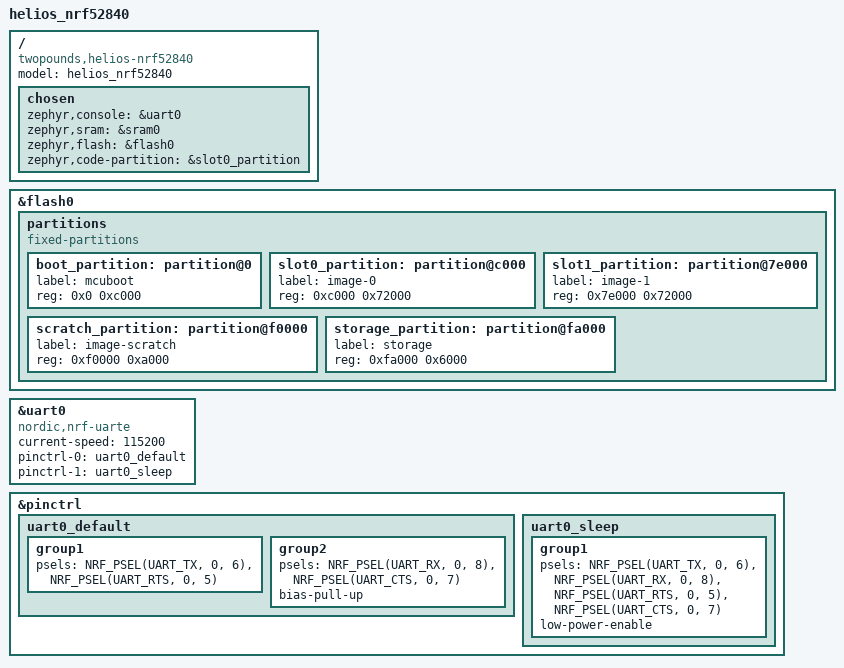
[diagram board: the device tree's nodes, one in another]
// Copyright (c) 2023 Nordic Semiconductor ASA
// SPDX-License-Identifier: Apache-2.0

/dts-v1/;
#include <nordic/nrf52840_qiaa.dtsi>

/ {
	model = "helios_nrf52840";
	compatible = "twopounds,helios-nrf52840";

	chosen {
		// zephyr,console = &cdc_acm_uart1; // original from manuel
		zephyr,console = &uart0; // inserted by jowi 5.9.2023
		zephyr,sram = &sram0;
		zephyr,flash = &flash0;
		zephyr,code-partition = &slot0_partition;
	};
};

//zephyr_udc0: &usbd {
//	compatible = "nordic,nrf-usbd";
//	status = "okay";
//	cdc_acm_uart1: cdc_acm_uart1 {
//		compatible = "zephyr,cdc-acm-uart";
//	};
//};


&flash0 {
	partitions {
		compatible = "fixed-partitions";
		#address-cells = <1>;
		#size-cells = <1>;

		boot_partition: partition@0 {
			label = "mcuboot";
			reg = <0x0 0xc000>;
		};
		slot0_partition: partition@c000 {
			label = "image-0";
			reg = <0xc000 0x72000>;
		};
		slot1_partition: partition@7e000 {
			label = "image-1";
			reg = <0x7e000 0x72000>;
		};
		scratch_partition: partition@f0000 {
			label = "image-scratch";
			reg = <0xf0000 0xa000>;
		};
		storage_partition: partition@fa000 {
			label = "storage";
			reg = <0xfa000 0x6000>;
		};
	};
};

&uart0 {
	compatible = "nordic,nrf-uarte";
	status = "okay";
	current-speed = <115200>;
	pinctrl-0 = <&uart0_default>;
	pinctrl-1 = <&uart0_sleep>;
	pinctrl-names = "default", "sleep";
};

&pinctrl {
	uart0_default: uart0_default {
		group1 {
			psels = <NRF_PSEL(UART_TX, 0, 6)>,
				<NRF_PSEL(UART_RTS, 0, 5)>;
		};
		group2 {
			psels = <NRF_PSEL(UART_RX, 0, 8)>,
				<NRF_PSEL(UART_CTS, 0, 7)>;
			bias-pull-up;
		};
	};

	uart0_sleep: uart0_sleep {
		group1 {
			psels = <NRF_PSEL(UART_TX, 0, 6)>,
				<NRF_PSEL(UART_RX, 0, 8)>,
				<NRF_PSEL(UART_RTS, 0, 5)>,
				<NRF_PSEL(UART_CTS, 0, 7)>;
			low-power-enable;
		};
	};
};

